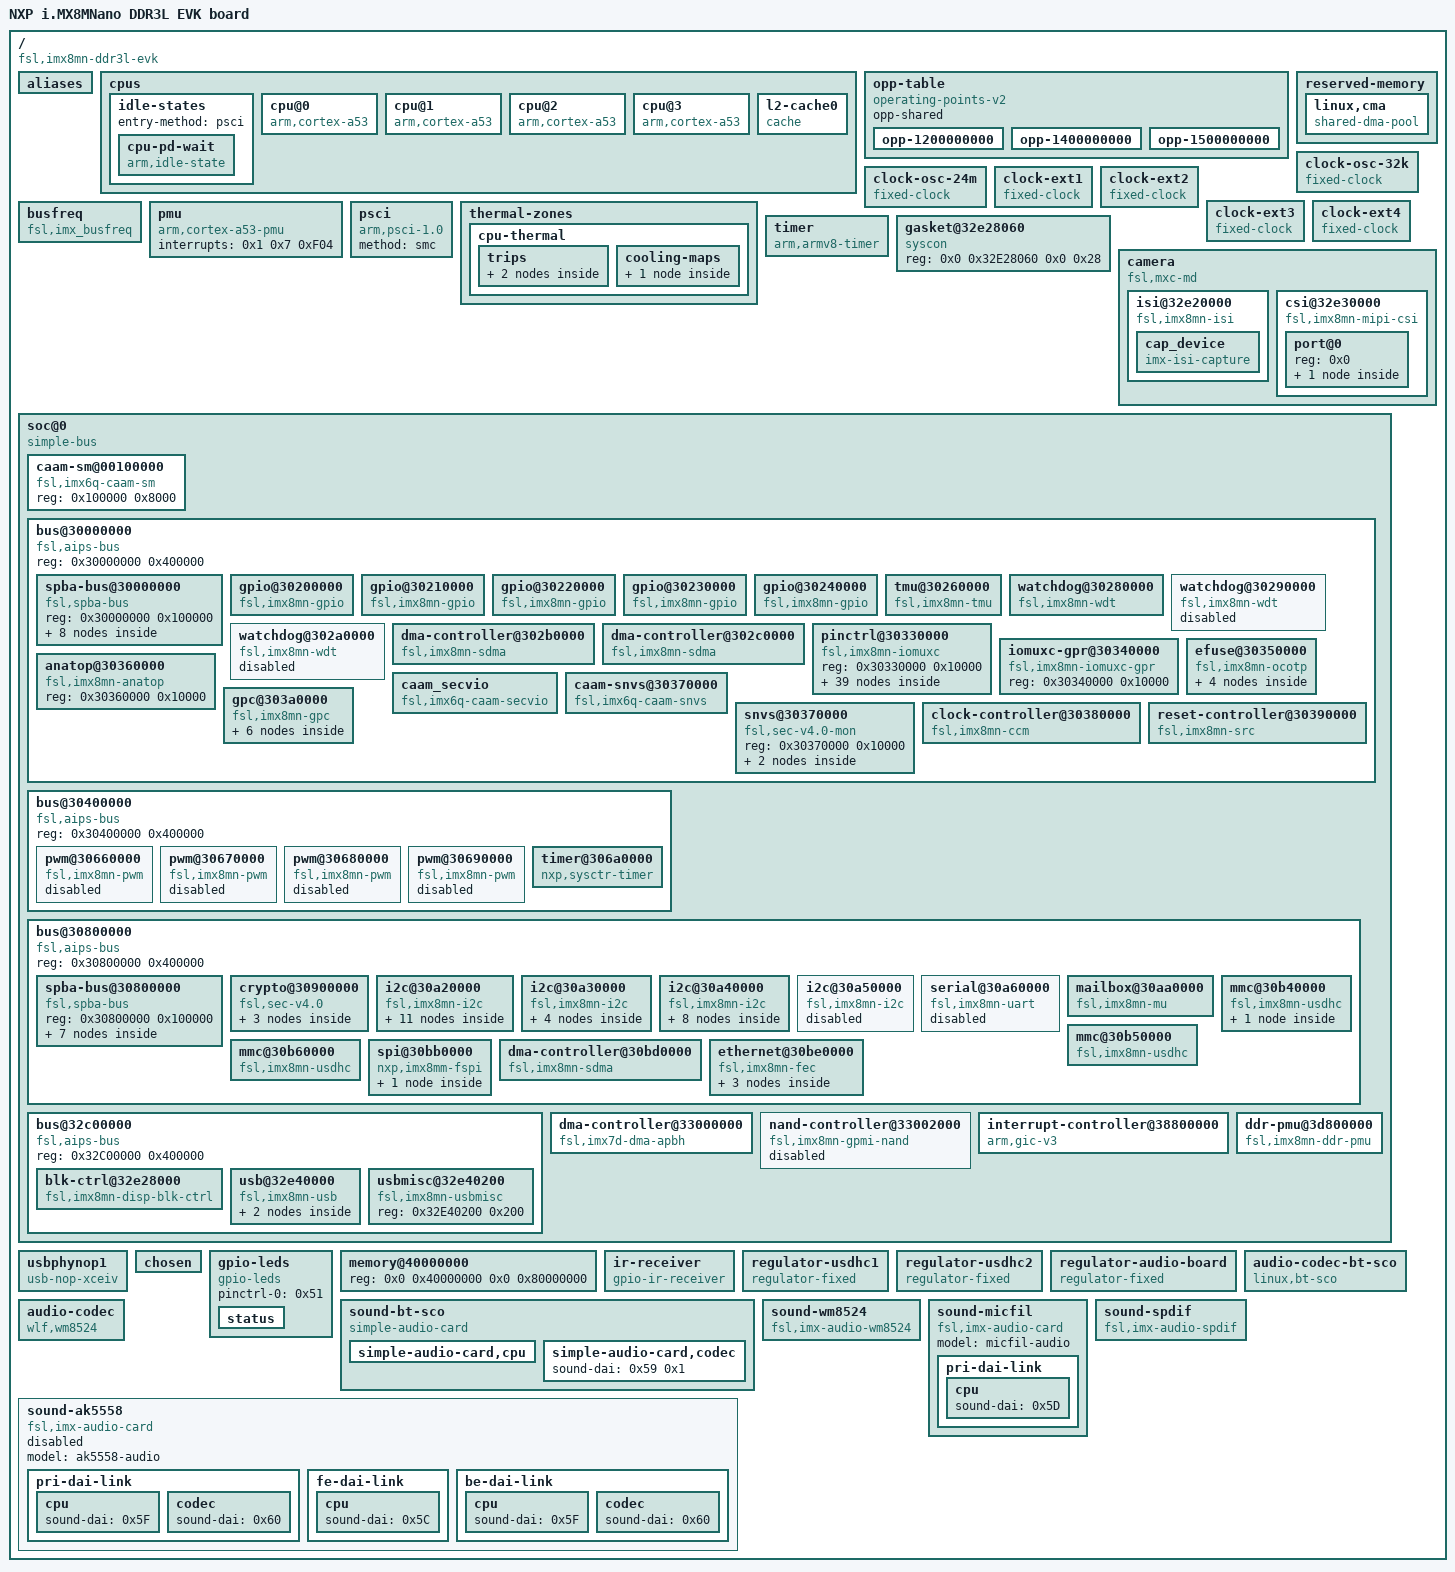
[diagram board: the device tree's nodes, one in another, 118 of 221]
/dts-v1/;
// version: 17
// last_comp_version: 16
// boot_cpuid_phys: 0x0

/ {
    interrupt-parent = <0x1>;
    #address-cells = <0x2>;
    #size-cells = <0x2>;
    model = "NXP i.MX8MNano DDR3L EVK board";
    compatible = "fsl,imx8mn-ddr3l-evk", "fsl,imx8mn";
    aliases {
        ethernet0 = "/soc@0/bus@30800000/ethernet@30be0000";
        gpio0 = "/soc@0/bus@30000000/gpio@30200000";
        gpio1 = "/soc@0/bus@30000000/gpio@30210000";
        gpio2 = "/soc@0/bus@30000000/gpio@30220000";
        gpio3 = "/soc@0/bus@30000000/gpio@30230000";
        gpio4 = "/soc@0/bus@30000000/gpio@30240000";
        i2c0 = "/soc@0/bus@30800000/i2c@30a20000";
        i2c1 = "/soc@0/bus@30800000/i2c@30a30000";
        i2c2 = "/soc@0/bus@30800000/i2c@30a40000";
        i2c3 = "/soc@0/bus@30800000/i2c@30a50000";
        mmc0 = "/soc@0/bus@30800000/mmc@30b40000";
        mmc1 = "/soc@0/bus@30800000/mmc@30b50000";
        mmc2 = "/soc@0/bus@30800000/mmc@30b60000";
        serial0 = "/soc@0/bus@30800000/spba-bus@30800000/serial@30860000";
        serial1 = "/soc@0/bus@30800000/spba-bus@30800000/serial@30890000";
        serial2 = "/soc@0/bus@30800000/spba-bus@30800000/serial@30880000";
        serial3 = "/soc@0/bus@30800000/serial@30a60000";
        spi0 = "/soc@0/bus@30800000/spba-bus@30800000/spi@30820000";
        spi1 = "/soc@0/bus@30800000/spba-bus@30800000/spi@30830000";
        spi2 = "/soc@0/bus@30800000/spba-bus@30800000/spi@30840000";
        isi0 = "/camera/isi@32e20000";
        csi0 = "/camera/csi@32e30000";
    };
    cpus {
        #address-cells = <0x1>;
        #size-cells = <0x0>;
        idle-states {
            entry-method = "psci";
            cpu-pd-wait {
                compatible = "arm,idle-state";
                arm,psci-suspend-param = <0x10033>;
                local-timer-stop;
                entry-latency-us = <0x3E8>;
                exit-latency-us = <0x2BC>;
                min-residency-us = <0xA8C>;
                phandle = <0x6>;
            };
        };
        cpu@0 {
            device_type = "cpu";
            compatible = "arm,cortex-a53";
            reg = <0x0>;
            clock-latency = <0xEE6C>;
            clocks = <0x2 0xBF>;
            enable-method = "psci";
            i-cache-size = <0x8000>;
            i-cache-line-size = <0x40>;
            i-cache-sets = <0x100>;
            d-cache-size = <0x8000>;
            d-cache-line-size = <0x40>;
            d-cache-sets = <0x80>;
            next-level-cache = <0x3>;
            operating-points-v2 = <0x4>;
            nvmem-cells = <0x5>;
            nvmem-cell-names = "speed_grade";
            cpu-idle-states = <0x6>;
            #cooling-cells = <0x2>;
            cpu-supply = <0x7>;
            phandle = <0xA>;
        };
        cpu@1 {
            device_type = "cpu";
            compatible = "arm,cortex-a53";
            reg = <0x1>;
            clock-latency = <0xEE6C>;
            clocks = <0x2 0xBF>;
            enable-method = "psci";
            i-cache-size = <0x8000>;
            i-cache-line-size = <0x40>;
            i-cache-sets = <0x100>;
            d-cache-size = <0x8000>;
            d-cache-line-size = <0x40>;
            d-cache-sets = <0x80>;
            next-level-cache = <0x3>;
            operating-points-v2 = <0x4>;
            cpu-idle-states = <0x6>;
            #cooling-cells = <0x2>;
            cpu-supply = <0x7>;
            phandle = <0xB>;
        };
        cpu@2 {
            device_type = "cpu";
            compatible = "arm,cortex-a53";
            reg = <0x2>;
            clock-latency = <0xEE6C>;
            clocks = <0x2 0xBF>;
            enable-method = "psci";
            i-cache-size = <0x8000>;
            i-cache-line-size = <0x40>;
            i-cache-sets = <0x100>;
            d-cache-size = <0x8000>;
            d-cache-line-size = <0x40>;
            d-cache-sets = <0x80>;
            next-level-cache = <0x3>;
            operating-points-v2 = <0x4>;
            cpu-idle-states = <0x6>;
            #cooling-cells = <0x2>;
            cpu-supply = <0x7>;
            phandle = <0xC>;
        };
        cpu@3 {
            device_type = "cpu";
            compatible = "arm,cortex-a53";
            reg = <0x3>;
            clock-latency = <0xEE6C>;
            clocks = <0x2 0xBF>;
            enable-method = "psci";
            i-cache-size = <0x8000>;
            i-cache-line-size = <0x40>;
            i-cache-sets = <0x100>;
            d-cache-size = <0x8000>;
            d-cache-line-size = <0x40>;
            d-cache-sets = <0x80>;
            next-level-cache = <0x3>;
            operating-points-v2 = <0x4>;
            cpu-idle-states = <0x6>;
            #cooling-cells = <0x2>;
            cpu-supply = <0x7>;
            phandle = <0xD>;
        };
        l2-cache0 {
            compatible = "cache";
            cache-level = <0x2>;
            cache-size = <0x80000>;
            cache-line-size = <0x40>;
            cache-sets = <0x200>;
            phandle = <0x3>;
        };
    };
    opp-table {
        compatible = "operating-points-v2";
        opp-shared;
        phandle = <0x4>;
        opp-1200000000 {
            opp-hz = <0x0 0x47868C00>;
            opp-microvolt = <0xCF850>;
            opp-supported-hw = <0xB00 0x7>;
            clock-latency-ns = <0x249F0>;
            opp-suspend;
        };
        opp-1400000000 {
            opp-hz = <0x0 0x53724E00>;
            opp-microvolt = <0xE7EF0>;
            opp-supported-hw = <0x300 0x7>;
            clock-latency-ns = <0x249F0>;
            opp-suspend;
        };
        opp-1500000000 {
            opp-hz = <0x0 0x59682F00>;
            opp-microvolt = <0xF4240>;
            opp-supported-hw = <0x100 0x3>;
            clock-latency-ns = <0x249F0>;
            opp-suspend;
        };
    };
    reserved-memory {
        #address-cells = <0x2>;
        #size-cells = <0x2>;
        ranges;
        linux,cma {
            compatible = "shared-dma-pool";
            reusable;
            size = <0x0 0x28000000>;
            alloc-ranges = <0x0 0x40000000 0x0 0x40000000>;
            linux,cma-default;
        };
    };
    clock-osc-32k {
        compatible = "fixed-clock";
        #clock-cells = <0x0>;
        clock-frequency = <0x8000>;
        clock-output-names = "osc_32k";
        phandle = <0x1B>;
    };
    clock-osc-24m {
        compatible = "fixed-clock";
        #clock-cells = <0x0>;
        clock-frequency = <0x16E3600>;
        clock-output-names = "osc_24m";
        phandle = <0x1C>;
    };
    clock-ext1 {
        compatible = "fixed-clock";
        #clock-cells = <0x0>;
        clock-frequency = <0x7ED6B40>;
        clock-output-names = "clk_ext1";
        phandle = <0x1D>;
    };
    clock-ext2 {
        compatible = "fixed-clock";
        #clock-cells = <0x0>;
        clock-frequency = <0x7ED6B40>;
        clock-output-names = "clk_ext2";
        phandle = <0x1E>;
    };
    clock-ext3 {
        compatible = "fixed-clock";
        #clock-cells = <0x0>;
        clock-frequency = <0x7ED6B40>;
        clock-output-names = "clk_ext3";
        phandle = <0x1F>;
    };
    clock-ext4 {
        compatible = "fixed-clock";
        #clock-cells = <0x0>;
        clock-frequency = <0x7ED6B40>;
        clock-output-names = "clk_ext4";
        phandle = <0x20>;
    };
    busfreq {
        compatible = "fsl,imx_busfreq";
        clocks = <0x2 0x29 0x2 0x59 0x2 0x5A 0x2 0x5A 0x2 0x58 0x2 0x5B 0x2 0x30 0x2 0x32 0x2 0x3F 0x2 0x53 0x2 0x54 0x2 0x4B 0x2 0x2 0x2 0x38 0x2 0x15>;
        clock-names = "dram_pll", "dram_alt_src", "dram_apb_src", "dram_apb_pre_div", "dram_core", "dram_alt_root", "sys_pll1_40m", "sys_pll1_100m", "sys_pll2_333m", "noc_div", "ahb_div", "main_axi_src", "osc_24m", "sys_pll1_800m", "dram_pll_div";
    };
    pmu {
        compatible = "arm,cortex-a53-pmu";
        interrupts = <0x1 0x7 0xF04>;
    };
    psci {
        compatible = "arm,psci-1.0";
        method = "smc";
    };
    thermal-zones {
        cpu-thermal {
            polling-delay-passive = <0xFA>;
            polling-delay = <0x7D0>;
            thermal-sensors = <0x8>;
            trips {
                trip0 {
                    temperature = <0x14C08>;
                    hysteresis = <0x7D0>;
                    type = "passive";
                    phandle = <0x9>;
                };
                trip1 {
                    temperature = <0x17318>;
                    hysteresis = <0x7D0>;
                    type = "critical";
                };
            };
            cooling-maps {
                map0 {
                    trip = <0x9>;
                    cooling-device = <0xA 0xFFFFFFFF 0xFFFFFFFF 0xB 0xFFFFFFFF 0xFFFFFFFF 0xC 0xFFFFFFFF 0xFFFFFFFF 0xD 0xFFFFFFFF 0xFFFFFFFF>;
                };
            };
        };
    };
    timer {
        compatible = "arm,armv8-timer";
        interrupts = <0x1 0xD 0xF08 0x1 0xE 0xF08 0x1 0xB 0xF08 0x1 0xA 0xF08>;
        clock-frequency = <0x7A1200>;
        arm,no-tick-in-suspend;
    };
    gasket@32e28060 {
        compatible = "syscon";
        reg = <0x0 0x32E28060 0x0 0x28>;
        phandle = <0xF>;
    };
    camera {
        compatible = "fsl,mxc-md", "simple-bus";
        #address-cells = <0x2>;
        #size-cells = <0x2>;
        ranges;
        status = "okay";
        isi@32e20000 {
            compatible = "fsl,imx8mn-isi";
            reg = <0x0 0x32E20000 0x0 0x2000>;
            power-domains = <0xE 0x3>;
            interrupts = <0x0 0x10 0x4>;
            interface = <0x2 0x0 0x2>;
            clocks = <0x2 0x4E 0x2 0x4F 0x2 0xB8 0x2 0xB9>;
            clock-names = "disp_axi", "disp_apb", "disp_axi_root", "disp_apb_root";
            assigned-clocks = <0x2 0xB8 0x2 0xB9>;
            assigned-clock-rates = <0x1DCD6500 0xBEBC200>;
            no-reset-control;
            status = "okay";
            cap_device {
                compatible = "imx-isi-capture";
                status = "okay";
            };
        };
        csi@32e30000 {
            compatible = "fsl,imx8mn-mipi-csi";
            reg = <0x0 0x32E30000 0x0 0x10000>;
            interrupts = <0x0 0x11 0x4>;
            clock-frequency = <0x13D92D40>;
            clocks = <0x2 0x81 0x2 0xB8 0x2 0xB9>;
            clock-names = "mipi_clk", "disp_axi", "disp_apb";
            assigned-clocks = <0x2 0x81>;
            assigned-clock-parents = <0x2 0x41>;
            assigned-clock-rates = <0x13D92D40>;
            bus-width = <0x4>;
            csi-gpr = <0xF>;
            power-domains = <0xE 0x1>;
            status = "okay";
            #address-cells = <0x1>;
            #size-cells = <0x0>;
            port@0 {
                reg = <0x0>;
                endpoint {
                    remote-endpoint = <0x10>;
                    data-lanes = <0x2>;
                    csis-hs-settle = <0xD>;
                    csis-clk-settle = <0x2>;
                    csis-wclk;
                    phandle = <0x35>;
                };
            };
        };
    };
    soc@0 {
        compatible = "simple-bus";
        #address-cells = <0x1>;
        #size-cells = <0x1>;
        ranges = <0x0 0x0 0x0 0x3E000000>;
        dma-ranges = <0x40000000 0x0 0x40000000 0xC0000000>;
        nvmem-cells = <0x11>;
        nvmem-cell-names = "soc_unique_id";
        caam-sm@00100000 {
            compatible = "fsl,imx6q-caam-sm";
            reg = <0x100000 0x8000>;
        };
        bus@30000000 {
            compatible = "fsl,aips-bus", "simple-bus";
            reg = <0x30000000 0x400000>;
            #address-cells = <0x1>;
            #size-cells = <0x1>;
            ranges;
            spba-bus@30000000 {
                compatible = "fsl,spba-bus", "simple-bus";
                #address-cells = <0x1>;
                #size-cells = <0x1>;
                reg = <0x30000000 0x100000>;
                ranges;
                sai@30020000 {
                    compatible = "fsl,imx8mn-sai", "fsl,imx8mq-sai";
                    reg = <0x30020000 0x10000>;
                    #sound-dai-cells = <0x0>;
                    interrupts = <0x0 0x60 0x4>;
                    clocks = <0x2 0x9E 0x2 0x0 0x2 0x9D 0x2 0x0 0x2 0x0>;
                    clock-names = "bus", "mclk0", "mclk1", "mclk2", "mclk3";
                    dmas = <0x12 0x2 0x2 0x0 0x12 0x3 0x2 0x0>;
                    dma-names = "rx", "tx";
                    status = "okay";
                    pinctrl-names = "default";
                    pinctrl-0 = <0x13>;
                    assigned-clocks = <0x2 0x5D>;
                    assigned-clock-parents = <0x2 0x26>;
                    assigned-clock-rates = <0x1770000>;
                    fsl,sai-mclk-direction-output;
                    phandle = <0x58>;
                };
                sai@30030000 {
                    compatible = "fsl,imx8mn-sai", "fsl,imx8mq-sai";
                    reg = <0x30030000 0x10000>;
                    #sound-dai-cells = <0x0>;
                    interrupts = <0x0 0x32 0x4>;
                    clocks = <0x2 0xA0 0x2 0x0 0x2 0x9F 0x2 0x0 0x2 0x0>;
                    clock-names = "bus", "mclk0", "mclk1", "mclk2", "mclk3";
                    dmas = <0x12 0x4 0x2 0x0 0x12 0x5 0x2 0x0>;
                    dma-names = "rx", "tx";
                    status = "okay";
                    pinctrl-names = "default";
                    pinctrl-0 = <0x14>;
                    assigned-clocks = <0x2 0x5E>;
                    assigned-clock-parents = <0x2 0x26>;
                    assigned-clock-rates = <0x1770000>;
                    fsl,sai-mclk-direction-output;
                    phandle = <0x5A>;
                };
                sai@30050000 {
                    compatible = "fsl,imx8mn-sai", "fsl,imx8mq-sai";
                    reg = <0x30050000 0x10000>;
                    #sound-dai-cells = <0x0>;
                    interrupts = <0x0 0x5A 0x4>;
                    clocks = <0x2 0xA2 0x2 0x0 0x2 0xA1 0x2 0x0 0x2 0x0 0x2 0x26 0x2 0x27>;
                    clock-names = "bus", "mclk0", "mclk1", "mclk2", "mclk3", "pll8k", "pll11k";
                    dmas = <0x12 0x8 0x19 0x0 0x12 0x9 0x19 0x0>;
                    dma-names = "rx", "tx";
                    fsl,shared-interrupt;
                    fsl,dataline = <0x0 0xF 0xF>;
                    status = "disabled";
                    pinctrl-names = "default";
                    pinctrl-0 = <0x15>;
                    assigned-clocks = <0x2 0x5F>;
                    assigned-clock-parents = <0x2 0x26>;
                    assigned-clock-rates = <0x2EE0000>;
                    fsl,sai-asynchronous;
                    fsl,sai-multi-lane;
                    fsl,sai-mclk-direction-output;
                    phandle = <0x5F>;
                };
                sai@30060000 {
                    compatible = "fsl,imx8mn-sai", "fsl,imx8mq-sai";
                    reg = <0x30060000 0x10000>;
                    #sound-dai-cells = <0x0>;
                    interrupts = <0x0 0x5A 0x4>;
                    clocks = <0x2 0xA4 0x2 0x0 0x2 0xA3 0x2 0x0 0x2 0x0>;
                    clock-names = "bus", "mclk0", "mclk1", "mclk2", "mclk3";
                    dmas = <0x12 0xA 0x2 0x0 0x12 0xB 0x2 0x0>;
                    dma-names = "rx", "tx";
                    status = "disabled";
                };
                audio-controller@30080000 {
                    compatible = "fsl,imx8mm-micfil";
                    reg = <0x30080000 0x10000>;
                    interrupts = <0x0 0x6D 0x4 0x0 0x6E 0x4 0x0 0x2C 0x4 0x0 0x2D 0x4>;
                    clocks = <0x2 0xB7 0x2 0xB6 0x2 0x26 0x2 0x27 0x2 0x6>;
                    clock-names = "ipg_clk", "ipg_clk_app", "pll8k", "pll11k", "clkext3";
                    dmas = <0x12 0x18 0x19 0x80000000>;
                    dma-names = "rx";
                    status = "okay";
                    #sound-dai-cells = <0x0>;
                    pinctrl-names = "default";
                    pinctrl-0 = <0x16>;
                    assigned-clocks = <0x2 0x86>;
                    assigned-clock-parents = <0x2 0x26>;
                    assigned-clock-rates = <0xBB80000>;
                    phandle = <0x5D>;
                };
                spdif@30090000 {
                    compatible = "fsl,imx35-spdif";
                    reg = <0x30090000 0x10000>;
                    interrupts = <0x0 0x6 0x4>;
                    clocks = <0x2 0x55 0x2 0x2 0x2 0x61 0x2 0x0 0x2 0x0 0x2 0x0 0x2 0x55 0x2 0x0 0x2 0x0 0x2 0x0 0x2 0x26 0x2 0x27>;
                    clock-names = "core", "rxtx0", "rxtx1", "rxtx2", "rxtx3", "rxtx4", "rxtx5", "rxtx6", "rxtx7", "spba", "pll8k", "pll11k";
                    dmas = <0x12 0x1C 0x12 0x0 0x12 0x1D 0x12 0x0>;
                    dma-names = "rx", "tx";
                    status = "okay";
                    pinctrl-names = "default";
                    pinctrl-0 = <0x17>;
                    assigned-clocks = <0x2 0x61>;
                    assigned-clock-parents = <0x2 0x26>;
                    assigned-clock-rates = <0x1770000>;
                    phandle = <0x5E>;
                };
                sai@300b0000 {
                    compatible = "fsl,imx8mn-sai", "fsl,imx8mq-sai";
                    reg = <0x300B0000 0x10000>;
                    #sound-dai-cells = <0x0>;
                    interrupts = <0x0 0x6F 0x4>;
                    clocks = <0x2 0xA6 0x2 0x0 0x2 0xA5 0x2 0x0 0x2 0x0>;
                    clock-names = "bus", "mclk0", "mclk1", "mclk2", "mclk3";
                    dmas = <0x12 0xC 0x2 0x0 0x12 0xD 0x2 0x0>;
                    dma-names = "rx", "tx";
                    status = "disabled";
                };
                easrc@300c0000 {
                    compatible = "fsl,imx8mn-easrc";
                    reg = <0x300C0000 0x10000>;
                    interrupts = <0x0 0x7A 0x4>;
                    clocks = <0x2 0xB4>;
                    clock-names = "mem";
                    dmas = <0x12 0x10 0x17 0x0 0x12 0x11 0x17 0x0 0x12 0x12 0x17 0x0 0x12 0x13 0x17 0x0 0x12 0x14 0x17 0x0 0x12 0x15 0x17 0x0 0x12 0x16 0x17 0x0 0x12 0x17 0x17 0x0>;
                    dma-names = "ctx0_rx", "ctx0_tx", "ctx1_rx", "ctx1_tx", "ctx2_rx", "ctx2_tx", "ctx3_rx", "ctx3_tx";
                    firmware-name = "imx/easrc/easrc-imx8mn.bin";
                    fsl,asrc-rate = <0xBB80>;
                    fsl,asrc-format = <0x2>;
                    status = "okay";
                    #sound-dai-cells = <0x0>;
                    phandle = <0x5C>;
                };
            };
            gpio@30200000 {
                compatible = "fsl,imx8mn-gpio", "fsl,imx35-gpio";
                reg = <0x30200000 0x10000>;
                interrupts = <0x0 0x40 0x4 0x0 0x41 0x4>;
                clocks = <0x2 0x8C>;
                gpio-controller;
                #gpio-cells = <0x2>;
                interrupt-controller;
                #interrupt-cells = <0x2>;
                gpio-ranges = <0x18 0x0 0xA 0x1E>;
                phandle = <0x28>;
            };
            gpio@30210000 {
                compatible = "fsl,imx8mn-gpio", "fsl,imx35-gpio";
                reg = <0x30210000 0x10000>;
                interrupts = <0x0 0x42 0x4 0x0 0x43 0x4>;
                clocks = <0x2 0x8D>;
                gpio-controller;
                #gpio-cells = <0x2>;
                interrupt-controller;
                #interrupt-cells = <0x2>;
                gpio-ranges = <0x18 0x0 0x28 0x15>;
                phandle = <0x2D>;
            };
            gpio@30220000 {
                compatible = "fsl,imx8mn-gpio", "fsl,imx35-gpio";
                reg = <0x30220000 0x10000>;
                interrupts = <0x0 0x44 0x4 0x0 0x45 0x4>;
                clocks = <0x2 0x8E>;
                gpio-controller;
                #gpio-cells = <0x2>;
                interrupt-controller;
                #interrupt-cells = <0x2>;
                gpio-ranges = <0x18 0x0 0x3D 0x1A>;
                phandle = <0x52>;
            };
            gpio@30230000 {
                compatible = "fsl,imx8mn-gpio", "fsl,imx35-gpio";
                reg = <0x30230000 0x10000>;
                interrupts = <0x0 0x46 0x4 0x0 0x47 0x4>;
                clocks = <0x2 0x8F>;
                gpio-controller;
                #gpio-cells = <0x2>;
                interrupt-controller;
                #interrupt-cells = <0x2>;
                gpio-ranges = <0x18 0x15 0x6C 0xB>;
                phandle = <0x48>;
            };
            gpio@30240000 {
                compatible = "fsl,imx8mn-gpio", "fsl,imx35-gpio";
                reg = <0x30240000 0x10000>;
                interrupts = <0x0 0x48 0x4 0x0 0x49 0x4>;
                clocks = <0x2 0x90>;
                gpio-controller;
                #gpio-cells = <0x2>;
                interrupt-controller;
                #interrupt-cells = <0x2>;
                gpio-ranges = <0x18 0x0 0x77 0x1E>;
                phandle = <0x2B>;
            };
            tmu@30260000 {
                compatible = "fsl,imx8mn-tmu", "fsl,imx8mm-tmu";
                reg = <0x30260000 0x10000>;
                clocks = <0x2 0xBE>;
                #thermal-sensor-cells = <0x0>;
                phandle = <0x8>;
            };
            watchdog@30280000 {
                compatible = "fsl,imx8mn-wdt", "fsl,imx21-wdt";
                reg = <0x30280000 0x10000>;
                interrupts = <0x0 0x4E 0x4>;
                clocks = <0x2 0xB0>;
                status = "okay";
                pinctrl-names = "default";
                pinctrl-0 = <0x19>;
                fsl,ext-reset-output;
            };
            watchdog@30290000 {
                compatible = "fsl,imx8mn-wdt", "fsl,imx21-wdt";
                reg = <0x30290000 0x10000>;
                interrupts = <0x0 0x4F 0x4>;
                clocks = <0x2 0xB1>;
                status = "disabled";
            };
            watchdog@302a0000 {
                compatible = "fsl,imx8mn-wdt", "fsl,imx21-wdt";
                reg = <0x302A0000 0x10000>;
                interrupts = <0x0 0xA 0x4>;
                clocks = <0x2 0xB2>;
                status = "disabled";
            };
            dma-controller@302b0000 {
                compatible = "fsl,imx8mn-sdma", "fsl,imx8mq-sdma", "fsl,imx7d-sdma";
                reg = <0x302B0000 0x10000>;
                interrupts = <0x0 0x22 0x4>;
                clocks = <0x2 0xBD 0x2 0xBD>;
                clock-names = "ipg", "ahb";
                #dma-cells = <0x3>;
                fsl,sdma-ram-script-name = "imx/sdma/sdma-imx7d.bin";
            };
            dma-controller@302c0000 {
                compatible = "fsl,imx8mn-sdma", "fsl,imx8mq-sdma", "fsl,imx7d-sdma";
                reg = <0x302C0000 0x10000>;
                interrupts = <0x0 0x67 0x4>;
                clocks = <0x2 0xA8 0x2 0xA8>;
                clock-names = "ipg", "ahb";
                #dma-cells = <0x3>;
                fsl,sdma-ram-script-name = "imx/sdma/sdma-imx7d.bin";
                phandle = <0x12>;
            };
            pinctrl@30330000 {
                compatible = "fsl,imx8mn-iomuxc";
                reg = <0x30330000 0x10000>;
                phandle = <0x18>;
                csi_pwn_grp {
                    fsl,pins = <0x44 0x2AC 0x0 0x0 0x0 0x19>;
                    phandle = <0x33>;
                };
                csi_rst_grp {
                    fsl,pins = <0x40 0x2A8 0x0 0x0 0x0 0x19 0x60 0x2C8 0x0 0x6 0x0 0x59>;
                    phandle = <0x34>;
                };
                ir-recv {
                    fsl,pins = <0x5C 0x2C4 0x0 0x0 0x0 0x4F>;
                };
                fec1grp {
                    fsl,pins = <0x68 0x2D0 0x0 0x0 0x0 0x3 0x6C 0x2D4 0x4C0 0x0 0x1 0x3 0x70 0x2D8 0x0 0x0 0x0 0x1F 0x74 0x2DC 0x0 0x0 0x0 0x1F 0x78 0x2E0 0x0 0x0 0x0 0x1F 0x7C 0x2E4 0x0 0x0 0x0 0x1F 0x9C 0x304 0x0 0x0 0x0 0x91 0x98 0x300 0x0 0x0 0x0 0x91 0x94 0x2FC 0x554 0x0 0x0 0x91 0x90 0x2F8 0x57C 0x0 0x0 0x91 0x84 0x2EC 0x0 0x0 0x0 0x1F 0x8C 0x2F4 0x0 0x0 0x0 0x91 0x88 0x2F0 0x574 0x0 0x0 0x91 0x80 0x2E8 0x0 0x0 0x0 0x1F 0x1B4 0x41C 0x0 0x5 0x0 0x19>;
                    phandle = <0x46>;
                };
                flexspigrp {
                    fsl,pins = <0xF4 0x35C 0x0 0x1 0x0 0x1C2 0xF8 0x360 0x0 0x1 0x0 0x82 0x10C 0x374 0x0 0x1 0x0 0x82 0x110 0x378 0x0 0x1 0x0 0x82 0x114 0x37C 0x0 0x1 0x0 0x82 0x118 0x380 0x0 0x1 0x0 0x82>;
                    phandle = <0x43>;
                };
                gpioledgrp {
                    fsl,pins = <0x134 0x39C 0x0 0x5 0x0 0x19>;
                    phandle = <0x51>;
                };
                i2c2grp-gpio {
                    fsl,pins = <0x21C 0x484 0x0 0x5 0x0 0x1C3 0x220 0x488 0x0 0x5 0x0 0x1C3>;
                    phandle = <0x2A>;
                };
                synaptics_dsx_iogrp {
                    fsl,pins = <0x4C 0x2B4 0x0 0x0 0x0 0x19>;
                };
                gpiowlfgrp {
                    fsl,pins = <0x230 0x498 0x0 0x5 0x0 0xD6>;
                    phandle = <0x56>;
                };
                irgrp {
                    fsl,pins = <0x5C 0x2C4 0x0 0x0 0x0 0x4F>;
                    phandle = <0x53>;
                };
                i2c1grp {
                    fsl,pins = <0x214 0x47C 0x55C 0x0 0x0 0x400001C3 0x218 0x480 0x56C 0x0 0x0 0x400001C3>;
                    phandle = <0x26>;
                };
                i2c2grp {
                    fsl,pins = <0x21C 0x484 0x5D0 0x0 0x0 0x400001C3 0x220 0x488 0x560 0x0 0x0 0x400001C3>;
                    phandle = <0x29>;
                };
                i2c3grp {
                    fsl,pins = <0x224 0x48C 0x588 0x0 0x0 0x400001C3 0x228 0x490 0x5BC 0x0 0x0 0x400001C3>;
                    phandle = <0x2F>;
                };
                i2c3grp-gpio {
                    fsl,pins = <0x224 0x48C 0x0 0x5 0x0 0x1C3 0x228 0x490 0x0 0x5 0x0 0x1C3>;
                    phandle = <0x30>;
                };
                pmicirqgrp {
                    fsl,pins = <0x34 0x29C 0x0 0x0 0x0 0x141>;
                    phandle = <0x27>;
                };
                mipi_dsi_en {
                    fsl,pins = <0x48 0x2B0 0x0 0x0 0x0 0x16>;
                };
                pdmgrp {
                    fsl,pins = <0x158 0x3C0 0x594 0x0 0x0 0xD6 0x144 0x3AC 0x0 0x4 0x0 0xD6 0x140 0x3A8 0x4E4 0x0 0x0 0xD6 0x148 0x3B0 0x534 0x4 0x0 0xD6 0x14C 0x3B4 0x538 0x4 0x0 0xD6 0x150 0x3B8 0x53C 0x4 0x0 0xD6 0x154 0x3BC 0x540 0x4 0x0 0xD6>;
                    phandle = <0x16>;
                };
                sai5grp {
                    fsl,pins = <0x158 0x3C0 0x594 0x0 0x0 0xD6 0x144 0x3AC 0x4D0 0x0 0x0 0xD6 0x140 0x3A8 0x4E4 0x0 0x0 0xD6 0x148 0x3B0 0x4D4 0x0 0x0 0xD6 0x14C 0x3B4 0x4D8 0x0 0x0 0xD6 0x150 0x3B8 0x4DC 0x0 0x0 0xD6 0x154 0x3BC 0x4E0 0x0 0x0 0xD6>;
                    phandle = <0x15>;
                };
                regusdhc2vmmcgrp {
                    fsl,pins = <0xEC 0x354 0x0 0x5 0x0 0x41>;
                    phandle = <0x55>;
                };
                sai2grp {
                    fsl,pins = <0x1C0 0x428 0x0 0x0 0x0 0xD6 0x1BC 0x424 0x0 0x0 0x0 0xD6 0x1C4 0x42C 0x0 0x0 0x0 0xD6 0x1B8 0x420 0x0 0x0 0x0 0xD6>;
                    phandle = <0x13>;
                };
                sai3grp {
                    fsl,pins = <0x1D8 0x440 0x0 0x0 0x0 0xD6 0x1DC 0x444 0x0 0x0 0x0 0xD6 0x1E4 0x44C 0x5C0 0x0 0x0 0xD6 0x1E0 0x448 0x0 0x0 0x0 0xD6>;
                    phandle = <0x14>;
                };
                spdif1grp {
                    fsl,pins = <0x1E8 0x450 0x0 0x0 0x0 0xD6 0x1EC 0x454 0x5CC 0x0 0x0 0xD6>;
                    phandle = <0x17>;
                };
                typec1grp {
                    fsl,pins = <0xCC 0x334 0x0 0x5 0x0 0x159>;
                    phandle = <0x2C>;
                };
                uart1grp {
                    fsl,pins = <0x234 0x49C 0x4F4 0x0 0x0 0x140 0x238 0x4A0 0x0 0x0 0x0 0x140 0x244 0x4AC 0x0 0x1 0x0 0x140 0x248 0x4B0 0x4F0 0x1 0x1 0x140>;
                    phandle = <0x23>;
                };
                uart2grp {
                    fsl,pins = <0x23C 0x4A4 0x4FC 0x0 0x0 0x140 0x240 0x4A8 0x0 0x0 0x0 0x140>;
                    phandle = <0x25>;
                };
                uart3grp {
                    fsl,pins = <0x1F4 0x45C 0x504 0x1 0x0 0x140 0x1F8 0x460 0x0 0x1 0x0 0x140 0x200 0x468 0x500 0x1 0x1 0x140 0x1FC 0x464 0x0 0x1 0x0 0x140>;
                    phandle = <0x24>;
                };
                regusdhc1vmmcgrp {
                    fsl,pins = <0xC8 0x330 0x0 0x5 0x0 0x141>;
                    phandle = <0x54>;
                };
                usdhc1grp {
                    fsl,pins = <0xA0 0x308 0x0 0x0 0x0 0x190 0xA4 0x30C 0x0 0x0 0x0 0x1D0 0xA8 0x310 0x0 0x0 0x0 0x1D0 0xAC 0x314 0x0 0x0 0x0 0x1D0 0xB0 0x318 0x0 0x0 0x0 0x1D0 0xB4 0x31C 0x0 0x0 0x0 0x1D0>;
                    phandle = <0x36>;
                };
                usdhc1grp100mhz {
                    fsl,pins = <0xA0 0x308 0x0 0x0 0x0 0x194 0xA4 0x30C 0x0 0x0 0x0 0x1D4 0xA8 0x310 0x0 0x0 0x0 0x1D4 0xAC 0x314 0x0 0x0 0x0 0x1D4 0xB0 0x318 0x0 0x0 0x0 0x1D4 0xB4 0x31C 0x0 0x0 0x0 0x1D4>;
                    phandle = <0x38>;
                };
                usdhc1grp200mhz {
                    fsl,pins = <0xA0 0x308 0x0 0x0 0x0 0x196 0xA4 0x30C 0x0 0x0 0x0 0x1D6 0xA8 0x310 0x0 0x0 0x0 0x1D6 0xAC 0x314 0x0 0x0 0x0 0x1D6 0xB0 0x318 0x0 0x0 0x0 0x1D6 0xB4 0x31C 0x0 0x0 0x0 0x1D6>;
                    phandle = <0x39>;
                };
                usdhc2gpiogrp {
                    fsl,pins = <0x64 0x2CC 0x0 0x0 0x0 0x1C4>;
                    phandle = <0x3C>;
                };
                usdhc2grp {
                    fsl,pins = <0xD4 0x33C 0x0 0x0 0x0 0x190 0xD8 0x340 0x0 0x0 0x0 0x1D0 0xDC 0x344 0x0 0x0 0x0 0x1D0 0xE0 0x348 0x0 0x0 0x0 0x1D0 0xE4 0x34C 0x0 0x0 0x0 0x1D0 0xE8 0x350 0x0 0x0 0x0 0x1D0 0x38 0x2A0 0x0 0x1 0x0 0x1D0>;
                    phandle = <0x3B>;
                };
                usdhc2-100mhzgrp {
                    fsl,pins = <0xD4 0x33C 0x0 0x0 0x0 0x194 0xD8 0x340 0x0 0x0 0x0 0x1D4 0xDC 0x344 0x0 0x0 0x0 0x1D4 0xE0 0x348 0x0 0x0 0x0 0x1D4 0xE4 0x34C 0x0 0x0 0x0 0x1D4 0xE8 0x350 0x0 0x0 0x0 0x1D4 0x38 0x2A0 0x0 0x1 0x0 0x1D0>;
                    phandle = <0x3D>;
                };
                usdhc2-200mhzgrp {
                    fsl,pins = <0xD4 0x33C 0x0 0x0 0x0 0x196 0xD8 0x340 0x0 0x0 0x0 0x1D6 0xDC 0x344 0x0 0x0 0x0 0x1D6 0xE0 0x348 0x0 0x0 0x0 0x1D6 0xE4 0x34C 0x0 0x0 0x0 0x1D6 0xE8 0x350 0x0 0x0 0x0 0x1D6 0x38 0x2A0 0x0 0x1 0x0 0x1D0>;
                    phandle = <0x3E>;
                };
                usdhc3grp {
                    fsl,pins = <0x138 0x3A0 0x5A0 0x2 0x0 0x40000190 0x13C 0x3A4 0x5DC 0x2 0x0 0x1D0 0x11C 0x384 0x5B4 0x2 0x0 0x1D0 0x120 0x388 0x5B0 0x2 0x0 0x1D0 0x124 0x38C 0x5E4 0x2 0x0 0x1D0 0x128 0x390 0x5E0 0x2 0x0 0x1D0 0x130 0x398 0x558 0x2 0x0 0x1D0 0x100 0x368 0x550 0x2 0x0 0x1D0 0x104 0x36C 0x584 0x2 0x0 0x1D0 0x108 0x370 0x54C 0x2 0x0 0x1D0 0xFC 0x364 0x59C 0x2 0x0 0x190>;
                    phandle = <0x40>;
                };
                usdhc3-100mhzgrp {
                    fsl,pins = <0x138 0x3A0 0x5A0 0x2 0x0 0x40000194 0x13C 0x3A4 0x5DC 0x2 0x0 0x1D4 0x11C 0x384 0x5B4 0x2 0x0 0x1D4 0x120 0x388 0x5B0 0x2 0x0 0x1D4 0x124 0x38C 0x5E4 0x2 0x0 0x1D4 0x128 0x390 0x5E0 0x2 0x0 0x1D4 0x130 0x398 0x558 0x2 0x0 0x1D4 0x100 0x368 0x550 0x2 0x0 0x1D4 0x104 0x36C 0x584 0x2 0x0 0x1D4 0x108 0x370 0x54C 0x2 0x0 0x1D4 0xFC 0x364 0x59C 0x2 0x0 0x194>;
                    phandle = <0x41>;
                };
                usdhc3-200mhzgrp {
                    fsl,pins = <0x138 0x3A0 0x5A0 0x2 0x0 0x40000196 0x13C 0x3A4 0x5DC 0x2 0x0 0x1D6 0x11C 0x384 0x5B4 0x2 0x0 0x1D6 0x120 0x388 0x5B0 0x2 0x0 0x1D6 0x124 0x38C 0x5E4 0x2 0x0 0x1D6 0x128 0x390 0x5E0 0x2 0x0 0x1D6 0x130 0x398 0x558 0x2 0x0 0x1D6 0x100 0x368 0x550 0x2 0x0 0x1D6 0x104 0x36C 0x584 0x2 0x0 0x1D6 0x108 0x370 0x54C 0x2 0x0 0x1D6 0xFC 0x364 0x59C 0x2 0x0 0x196>;
                    phandle = <0x42>;
                };
                wdoggrp {
                    fsl,pins = <0x30 0x298 0x0 0x1 0x0 0x166>;
                    phandle = <0x19>;
                };
                wlangrp {
                    fsl,pins = <0x28 0x290 0x0 0x5 0x0 0x141 0xC4 0x32C 0x0 0x5 0x0 0x159>;
                    phandle = <0x37>;
                };
            };
            iomuxc-gpr@30340000 {
                compatible = "fsl,imx8mn-iomuxc-gpr", "syscon";
                reg = <0x30340000 0x10000>;
                phandle = <0x45>;
            };
            efuse@30350000 {
                compatible = "fsl,imx8mn-ocotp", "fsl,imx8mm-ocotp", "syscon", "simple-mfd";
                reg = <0x30350000 0x10000>;
                clocks = <0x2 0x96>;
                #address-cells = <0x1>;
                #size-cells = <0x1>;
                unique-id@4 {
                    reg = <0x4 0x8>;
                    phandle = <0x11>;
                };
                speed-grade@10 {
                    reg = <0x10 0x4>;
                    phandle = <0x5>;
                };
                mac-address@90 {
                    reg = <0x90 0x6>;
                    phandle = <0x44>;
                };
                imx8mn-soc {
                    compatible = "fsl,imx8mn-soc";
                    nvmem-cells = <0x11>;
                    nvmem-cell-names = "soc_unique_id";
                };
            };
            anatop@30360000 {
                compatible = "fsl,imx8mn-anatop", "fsl,imx8mm-anatop", "syscon";
                reg = <0x30360000 0x10000>;
            };
            caam_secvio {
                compatible = "fsl,imx6q-caam-secvio";
                interrupts = <0x0 0x14 0x4>;
                jtag-tamper = "disabled";
                watchdog-tamper = "enabled";
                internal-boot-tamper = "enabled";
                external-pin-tamper = "disabled";
            };
            caam-snvs@30370000 {
                compatible = "fsl,imx6q-caam-snvs";
                reg = <0x30370000 0x10000>;
                clocks = <0x2 0xD3>;
                clock-names = "ipg";
            };
            snvs@30370000 {
                compatible = "fsl,sec-v4.0-mon", "syscon", "simple-mfd";
                reg = <0x30370000 0x10000>;
                phandle = <0x1A>;
                snvs-rtc-lp {
                    compatible = "fsl,sec-v4.0-mon-rtc-lp";
                    regmap = <0x1A>;
                    offset = <0x34>;
                    interrupts = <0x0 0x13 0x4 0x0 0x14 0x4>;
                    clocks = <0x2 0xD3>;
                    clock-names = "snvs-rtc";
                };
                snvs-powerkey {
                    compatible = "fsl,sec-v4.0-pwrkey";
                    regmap = <0x1A>;
                    interrupts = <0x0 0x4 0x4>;
                    clocks = <0x2 0xD3>;
                    clock-names = "snvs-pwrkey";
                    linux,keycode = <0x74>;
                    wakeup-source;
                    status = "okay";
                };
            };
            clock-controller@30380000 {
                compatible = "fsl,imx8mn-ccm";
                reg = <0x30380000 0x10000>;
                #clock-cells = <0x1>;
                clocks = <0x1B 0x1C 0x1D 0x1E 0x1F 0x20>;
                clock-names = "osc_32k", "osc_24m", "clk_ext1", "clk_ext2", "clk_ext3", "clk_ext4";
                assigned-clocks = <0x2 0x42 0x2 0xD6 0x2 0x53 0x2 0x55 0x2 0x57 0x2 0x1B 0x2 0x14 0x2 0x12 0x2 0x13>;
                assigned-clock-parents = <0x2 0x38 0x2 0x2C 0x2 0x2F 0x2 0x38>;
                assigned-clock-rates = <0x0 0x0 0x0 0x17D78400 0x17D78400 0x23C34600 0x3DF582E0 0x17700000 0x15888000>;
                phandle = <0x2>;
            };
            reset-controller@30390000 {
                compatible = "fsl,imx8mn-src", "fsl,imx8mq-src", "syscon";
                reg = <0x30390000 0x10000>;
                interrupts = <0x0 0x59 0x4>;
                #reset-cells = <0x1>;
            };
            gpc@303a0000 {
                compatible = "fsl,imx8mn-gpc";
                reg = <0x303A0000 0x10000>;
                interrupt-parent = <0x1>;
                interrupts = <0x0 0x57 0x4>;
                pgc {
                    #address-cells = <0x1>;
                    #size-cells = <0x0>;
                    power-domain@0 {
                        #power-domain-cells = <0x0>;
                        reg = <0x0>;
                        clocks = <0x2 0x50>;
                        phandle = <0x4D>;
                    };
                    power-domain@1 {
                        #power-domain-cells = <0x0>;
                        reg = <0x1>;
                        phandle = <0x50>;
                    };
                    power-domain@2 {
                        #power-domain-cells = <0x0>;
                        reg = <0x2>;
                        clocks = <0x2 0xC1 0x2 0xD5 0x2 0xB3 0x2 0x52>;
                    };
                    power-domain@3 {
                        #power-domain-cells = <0x0>;
                        reg = <0x3>;
                        clocks = <0x2 0xB8 0x2 0xB9>;
                        phandle = <0x21>;
                    };
                    power-domain@4 {
                        #power-domain-cells = <0x0>;
                        reg = <0x4>;
                        power-domains = <0x21>;
                        phandle = <0x4A>;
                    };
                };
            };
        };
        bus@30400000 {
            compatible = "fsl,aips-bus", "simple-bus";
            reg = <0x30400000 0x400000>;
            #address-cells = <0x1>;
            #size-cells = <0x1>;
            ranges;
            pwm@30660000 {
                compatible = "fsl,imx8mn-pwm", "fsl,imx27-pwm";
                reg = <0x30660000 0x10000>;
                interrupts = <0x0 0x51 0x4>;
                clocks = <0x2 0x97 0x2 0x97>;
                clock-names = "ipg", "per";
                #pwm-cells = <0x3>;
                status = "disabled";
            };
            pwm@30670000 {
                compatible = "fsl,imx8mn-pwm", "fsl,imx27-pwm";
                reg = <0x30670000 0x10000>;
                interrupts = <0x0 0x52 0x4>;
                clocks = <0x2 0x98 0x2 0x98>;
                clock-names = "ipg", "per";
                #pwm-cells = <0x3>;
                status = "disabled";
            };
            pwm@30680000 {
                compatible = "fsl,imx8mn-pwm", "fsl,imx27-pwm";
                reg = <0x30680000 0x10000>;
                interrupts = <0x0 0x53 0x4>;
                clocks = <0x2 0x99 0x2 0x99>;
                clock-names = "ipg", "per";
                #pwm-cells = <0x3>;
                status = "disabled";
            };
            pwm@30690000 {
                compatible = "fsl,imx8mn-pwm", "fsl,imx27-pwm";
                reg = <0x30690000 0x10000>;
                interrupts = <0x0 0x54 0x4>;
                clocks = <0x2 0x9A 0x2 0x9A>;
                clock-names = "ipg", "per";
                #pwm-cells = <0x3>;
                status = "disabled";
            };
            timer@306a0000 {
                compatible = "nxp,sysctr-timer";
                reg = <0x306A0000 0x20000>;
                interrupts = <0x0 0x2F 0x4>;
                clocks = <0x1C>;
                clock-names = "per";
            };
        };
        bus@30800000 {
            compatible = "fsl,aips-bus", "simple-bus";
            reg = <0x30800000 0x400000>;
            #address-cells = <0x1>;
            #size-cells = <0x1>;
            ranges;
            spba-bus@30800000 {
                compatible = "fsl,spba-bus", "simple-bus";
                #address-cells = <0x1>;
                #size-cells = <0x1>;
                reg = <0x30800000 0x100000>;
                ranges;
                spi@30820000 {
                    compatible = "fsl,imx8mn-ecspi", "fsl,imx51-ecspi";
                    #address-cells = <0x1>;
                    #size-cells = <0x0>;
                    reg = <0x30820000 0x10000>;
                    interrupts = <0x0 0x1F 0x4>;
                    clocks = <0x2 0x88 0x2 0x88>;
                    clock-names = "ipg", "per";
                    dmas = <0x22 0x0 0x7 0x1 0x22 0x1 0x7 0x2>;
                    dma-names = "rx", "tx";
                    status = "disabled";
                };
                spi@30830000 {
                    compatible = "fsl,imx8mn-ecspi", "fsl,imx51-ecspi";
                    #address-cells = <0x1>;
                    #size-cells = <0x0>;
                    reg = <0x30830000 0x10000>;
                    interrupts = <0x0 0x20 0x4>;
                    clocks = <0x2 0x89 0x2 0x89>;
                    clock-names = "ipg", "per";
                    dmas = <0x22 0x2 0x7 0x1 0x22 0x3 0x7 0x2>;
                    dma-names = "rx", "tx";
                    status = "disabled";
                };
                spi@30840000 {
                    compatible = "fsl,imx8mn-ecspi", "fsl,imx51-ecspi";
                    #address-cells = <0x1>;
                    #size-cells = <0x0>;
                    reg = <0x30840000 0x10000>;
                    interrupts = <0x0 0x21 0x4>;
                    clocks = <0x2 0x8A 0x2 0x8A>;
                    clock-names = "ipg", "per";
                    dmas = <0x22 0x4 0x7 0x1 0x22 0x5 0x7 0x2>;
                    dma-names = "rx", "tx";
                    status = "disabled";
                };
                serial@30860000 {
                    compatible = "fsl,imx8mn-uart", "fsl,imx6q-uart";
                    reg = <0x30860000 0x10000>;
                    interrupts = <0x0 0x1A 0x4>;
                    clocks = <0x2 0xA9 0x2 0xA9>;
                    clock-names = "ipg", "per";
                    dmas = <0x22 0x16 0x4 0x0 0x22 0x17 0x4 0x0>;
                    dma-names = "rx", "tx";
                    status = "okay";
                    pinctrl-names = "default";
                    pinctrl-0 = <0x23>;
                    assigned-clocks = <0x2 0x6D>;
                    assigned-clock-parents = <0x2 0x31>;
                    fsl,uart-has-rtscts;
                    bluetooth {
                        compatible = "nxp,88w8987-bt";
                    };
                };
                serial@30880000 {
                    compatible = "fsl,imx8mn-uart", "fsl,imx6q-uart";
                    reg = <0x30880000 0x10000>;
                    interrupts = <0x0 0x1C 0x4>;
                    clocks = <0x2 0xAB 0x2 0xAB>;
                    clock-names = "ipg", "per";
                    dmas = <0x22 0x1A 0x4 0x0 0x22 0x1B 0x4 0x0>;
                    dma-names = "rx", "tx";
                    status = "okay";
                    pinctrl-names = "default";
                    pinctrl-0 = <0x24>;
                    assigned-clocks = <0x2 0x6F>;
                    assigned-clock-parents = <0x2 0x31>;
                    uart-has-rtscts;
                };
                serial@30890000 {
                    compatible = "fsl,imx8mn-uart", "fsl,imx6q-uart";
                    reg = <0x30890000 0x10000>;
                    interrupts = <0x0 0x1B 0x4>;
                    clocks = <0x2 0xAA 0x2 0xAA>;
                    clock-names = "ipg", "per";
                    status = "okay";
                    pinctrl-names = "default";
                    pinctrl-0 = <0x25>;
                };
            };
            crypto@30900000 {
                compatible = "fsl,sec-v4.0";
                #address-cells = <0x1>;
                #size-cells = <0x1>;
                reg = <0x30900000 0x40000>;
                ranges = <0x0 0x30900000 0x40000>;
                interrupts = <0x0 0x5B 0x4>;
                clocks = <0x2 0x54 0x2 0x56>;
                clock-names = "aclk", "ipg";
                jr@1000 {
                    compatible = "fsl,sec-v4.0-job-ring";
                    reg = <0x1000 0x1000>;
                    interrupts = <0x0 0x69 0x4>;
                    status = "disabled";
                };
                jr@2000 {
                    compatible = "fsl,sec-v4.0-job-ring";
                    reg = <0x2000 0x1000>;
                    interrupts = <0x0 0x6A 0x4>;
                };
                jr@3000 {
                    compatible = "fsl,sec-v4.0-job-ring";
                    reg = <0x3000 0x1000>;
                    interrupts = <0x0 0x72 0x4>;
                };
            };
            i2c@30a20000 {
                compatible = "fsl,imx8mn-i2c", "fsl,imx21-i2c";
                #address-cells = <0x1>;
                #size-cells = <0x0>;
                reg = <0x30A20000 0x10000>;
                interrupts = <0x0 0x23 0x4>;
                clocks = <0x2 0x91>;
                status = "okay";
                clock-frequency = <0x61A80>;
                pinctrl-names = "default";
                pinctrl-0 = <0x26>;
                pmic@25 {
                    compatible = "nxp,pca9450b";
                    reg = <0x25>;
                    pinctrl-names = "default";
                    pinctrl-0 = <0x27>;
                    interrupt-parent = <0x28>;
                    interrupts = <0x3 0x8>;
                    regulators {
                        BUCK1 {
                            regulator-name = "VDD_SOC_0V9";
                            regulator-min-microvolt = <0xCF850>;
                            regulator-max-microvolt = <0xE7EF0>;
                            regulator-boot-on;
                            regulator-always-on;
                            regulator-ramp-delay = <0xC35>;
                            phandle = <0x7>;
                        };
                        BUCK4 {
                            regulator-name = "VDD_3V3";
                            regulator-min-microvolt = <0x325AA0>;
                            regulator-max-microvolt = <0x325AA0>;
                            regulator-boot-on;
                            regulator-always-on;
                        };
                        BUCK5 {
                            regulator-name = "VDD_1V8";
                            regulator-min-microvolt = <0x1B7740>;
                            regulator-max-microvolt = <0x1B7740>;
                            regulator-boot-on;
                            regulator-always-on;
                        };
                        BUCK6 {
                            regulator-name = "NVCC_DRAM_1V35";
                            regulator-min-microvolt = <0x149970>;
                            regulator-max-microvolt = <0x149970>;
                            regulator-boot-on;
                            regulator-always-on;
                        };
                        LDO1 {
                            regulator-name = "NVCC_SNVS_1V8";
                            regulator-min-microvolt = <0x1B7740>;
                            regulator-max-microvolt = <0x1B7740>;
                            regulator-boot-on;
                            regulator-always-on;
                        };
                        LDO2 {
                            regulator-name = "VDD_SNVS_0V8";
                            regulator-min-microvolt = <0xC3500>;
                            regulator-max-microvolt = <0xC3500>;
                            regulator-boot-on;
                            regulator-always-on;
                        };
                        LDO3 {
                            regulator-name = "VDDA_1V8";
                            regulator-min-microvolt = <0x1B7740>;
                            regulator-max-microvolt = <0x1B7740>;
                            regulator-boot-on;
                            regulator-always-on;
                        };
                        LDO4 {
                            regulator-name = "VDD_PHY_1V2";
                            regulator-min-microvolt = <0x124F80>;
                            regulator-max-microvolt = <0x124F80>;
                            regulator-boot-on;
                            regulator-always-on;
                        };
                        LDO5 {
                            regulator-name = "NVCC_SD2";
                            regulator-min-microvolt = <0x1B7740>;
                            regulator-max-microvolt = <0x325AA0>;
                            regulator-boot-on;
                            regulator-always-on;
                        };
                    };
                };
            };
            i2c@30a30000 {
                compatible = "fsl,imx8mn-i2c", "fsl,imx21-i2c";
                #address-cells = <0x1>;
                #size-cells = <0x0>;
                reg = <0x30A30000 0x10000>;
                interrupts = <0x0 0x24 0x4>;
                clocks = <0x2 0x92>;
                status = "okay";
                clock-frequency = <0x61A80>;
                pinctrl-names = "default", "gpio";
                pinctrl-0 = <0x29>;
                pinctrl-1 = <0x2A>;
                scl-gpios = <0x2B 0x10 0x0>;
                sda-gpios = <0x2B 0x11 0x0>;
                tcpc@50 {
                    compatible = "nxp,ptn5110";
                    pinctrl-names = "default";
                    pinctrl-0 = <0x2C>;
                    reg = <0x50>;
                    interrupt-parent = <0x2D>;
                    interrupts = <0xB 0x8>;
                    status = "okay";
                    port {
                        endpoint {
                            remote-endpoint = <0x2E>;
                            phandle = <0x4E>;
                        };
                    };
                    connector {
                        compatible = "usb-c-connector";
                        label = "USB-C";
                        power-role = "dual";
                        data-role = "dual";
                        try-power-role = "sink";
                        source-pdos = <0x401912C>;
                        sink-pdos = <0x401912C 0x9901912C>;
                        op-sink-microwatt = <0xE4E1C0>;
                        self-powered;
                    };
                };
            };
            i2c@30a40000 {
                #address-cells = <0x1>;
                #size-cells = <0x0>;
                compatible = "fsl,imx8mn-i2c", "fsl,imx21-i2c";
                reg = <0x30A40000 0x10000>;
                interrupts = <0x0 0x25 0x4>;
                clocks = <0x2 0x93>;
                status = "okay";
                clock-frequency = <0x186A0>;
                pinctrl-names = "default", "gpio";
                pinctrl-0 = <0x2F>;
                pinctrl-1 = <0x30>;
                scl-gpios = <0x2B 0x12 0x0>;
                sda-gpios = <0x2B 0x13 0x0>;
                gpio@20 {
                    compatible = "ti,tca6416";
                    reg = <0x20>;
                    gpio-controller;
                    #gpio-cells = <0x2>;
                    phandle = <0x32>;
                };
                ak4458@10 {
                    #sound-dai-cells = <0x0>;
                    compatible = "asahi-kasei,ak4458";
                    reg = <0x10>;
                    AVDD-supply = <0x31>;
                    DVDD-supply = <0x31>;
                    status = "disabled";
                };
                ak4458@12 {
                    #sound-dai-cells = <0x0>;
                    compatible = "asahi-kasei,ak4458";
                    reg = <0x12>;
                    AVDD-supply = <0x31>;
                    DVDD-supply = <0x31>;
                    status = "disabled";
                };
                ak5558@13 {
                    #sound-dai-cells = <0x0>;
                    compatible = "asahi-kasei,ak5558";
                    reg = <0x13>;
                    reset-gpios = <0x32 0x3 0x1>;
                    AVDD-supply = <0x31>;
                    DVDD-supply = <0x31>;
                    status = "disabled";
                    phandle = <0x60>;
                };
                ak4497@11 {
                    #sound-dai-cells = <0x0>;
                    compatible = "asahi-kasei,ak4497";
                    reg = <0x11>;
                    reset-gpios = <0x32 0x5 0x1>;
                    AVDD-supply = <0x31>;
                    DVDD-supply = <0x31>;
                    status = "disabled";
                };
                ov5640_mipi@3c {
                    compatible = "ovti,ov5640";
                    reg = <0x3C>;
                    pinctrl-names = "default";
                    pinctrl-0 = <0x33 0x34>;
                    clocks = <0x2 0x7B>;
                    clock-names = "xclk";
                    assigned-clocks = <0x2 0x7B>;
                    assigned-clock-parents = <0x2 0x2>;
                    assigned-clock-rates = <0x16E3600>;
                    csi_id = <0x0>;
                    powerdown-gpios = <0x28 0x7 0x0>;
                    reset-gpios = <0x28 0x6 0x1>;
                    mclk = <0x16E3600>;
                    mclk_source = <0x0>;
                    mipi_csi;
                    status = "okay";
                    port {
                        endpoint {
                            remote-endpoint = <0x35>;
                            data-lanes = <0x1 0x2>;
                            clocks-lanes = <0x0>;
                            phandle = <0x10>;
                        };
                    };
                };
            };
            i2c@30a50000 {
                compatible = "fsl,imx8mn-i2c", "fsl,imx21-i2c";
                #address-cells = <0x1>;
                #size-cells = <0x0>;
                reg = <0x30A50000 0x10000>;
                interrupts = <0x0 0x26 0x4>;
                clocks = <0x2 0x94>;
                status = "disabled";
            };
            serial@30a60000 {
                compatible = "fsl,imx8mn-uart", "fsl,imx6q-uart";
                reg = <0x30A60000 0x10000>;
                interrupts = <0x0 0x1D 0x4>;
                clocks = <0x2 0xAC 0x2 0xAC>;
                clock-names = "ipg", "per";
                dmas = <0x22 0x1C 0x4 0x0 0x22 0x1D 0x4 0x0>;
                dma-names = "rx", "tx";
                status = "disabled";
            };
            mailbox@30aa0000 {
                compatible = "fsl,imx8mn-mu", "fsl,imx6sx-mu";
                reg = <0x30AA0000 0x10000>;
                interrupts = <0x0 0x58 0x4>;
                clocks = <0x2 0x95>;
                #mbox-cells = <0x2>;
            };
            mmc@30b40000 {
                compatible = "fsl,imx8mn-usdhc", "fsl,imx8mm-usdhc", "fsl,imx7d-usdhc";
                reg = <0x30B40000 0x10000>;
                interrupts = <0x0 0x16 0x4>;
                clocks = <0x2 0x56 0x2 0x4D 0x2 0xAE>;
                clock-names = "ipg", "ahb", "per";
                fsl,tuning-start-tap = <0x14>;
                fsl,tuning-step = <0x2>;
                bus-width = <0x4>;
                status = "okay";
                #address-cells = <0x1>;
                #size-cells = <0x0>;
                pinctrl-names = "default", "state_100mhz", "state_200mhz";
                pinctrl-0 = <0x36 0x37>;
                pinctrl-1 = <0x38 0x37>;
                pinctrl-2 = <0x39 0x37>;
                keep-power-in-suspend;
                non-removable;
                wakeup-source;
                fsl,sdio-async-interrupt-enabled;
                vmmc-supply = <0x3A>;
                wifi_wake_host {
                    compatible = "nxp,wifi-wake-host";
                    interrupt-parent = <0x2D>;
                    interrupts = <0x9 0x8>;
                    interrupt-names = "host-wake";
                };
            };
            mmc@30b50000 {
                compatible = "fsl,imx8mn-usdhc", "fsl,imx8mm-usdhc", "fsl,imx7d-usdhc";
                reg = <0x30B50000 0x10000>;
                interrupts = <0x0 0x17 0x4>;
                clocks = <0x2 0x56 0x2 0x4D 0x2 0xAF>;
                clock-names = "ipg", "ahb", "per";
                fsl,tuning-start-tap = <0x14>;
                fsl,tuning-step = <0x2>;
                bus-width = <0x4>;
                status = "okay";
                assigned-clocks = <0x2 0x68>;
                assigned-clock-rates = <0xBEBC200>;
                pinctrl-names = "default", "state_100mhz", "state_200mhz";
                pinctrl-0 = <0x3B 0x3C>;
                pinctrl-1 = <0x3D 0x3C>;
                pinctrl-2 = <0x3E 0x3C>;
                cd-gpios = <0x28 0xF 0x1>;
                vmmc-supply = <0x3F>;
            };
            mmc@30b60000 {
                compatible = "fsl,imx8mn-usdhc", "fsl,imx8mm-usdhc", "fsl,imx7d-usdhc";
                reg = <0x30B60000 0x10000>;
                interrupts = <0x0 0x18 0x4>;
                clocks = <0x2 0x56 0x2 0x4D 0x2 0xBC>;
                clock-names = "ipg", "ahb", "per";
                fsl,tuning-start-tap = <0x14>;
                fsl,tuning-step = <0x2>;
                bus-width = <0x8>;
                status = "okay";
                assigned-clocks = <0x2 0xBC>;
                assigned-clock-rates = <0x17D78400>;
                pinctrl-names = "default", "state_100mhz", "state_200mhz";
                pinctrl-0 = <0x40>;
                pinctrl-1 = <0x41>;
                pinctrl-2 = <0x42>;
                non-removable;
            };
            spi@30bb0000 {
                #address-cells = <0x1>;
                #size-cells = <0x0>;
                compatible = "nxp,imx8mm-fspi";
                reg = <0x30BB0000 0x10000 0x8000000 0x10000000>;
                reg-names = "fspi_base", "fspi_mmap";
                interrupts = <0x0 0x6B 0x4>;
                clocks = <0x2 0x9B 0x2 0x9B>;
                clock-names = "fspi_en", "fspi";
                status = "okay";
                pinctrl-names = "default";
                pinctrl-0 = <0x43>;
                flash@0 {
                    compatible = "jedec,spi-nor";
                    reg = <0x0>;
                    #address-cells = <0x1>;
                    #size-cells = <0x1>;
                    spi-max-frequency = <0x9E4F580>;
                    spi-tx-bus-width = <0x1>;
                    spi-rx-bus-width = <0x4>;
                };
            };
            dma-controller@30bd0000 {
                compatible = "fsl,imx8mn-sdma", "fsl,imx8mq-sdma", "fsl,imx7d-sdma";
                reg = <0x30BD0000 0x10000>;
                interrupts = <0x0 0x2 0x4>;
                clocks = <0x2 0xA7 0x2 0x54>;
                clock-names = "ipg", "ahb";
                #dma-cells = <0x3>;
                fsl,sdma-ram-script-name = "imx/sdma/sdma-imx7d.bin";
                phandle = <0x22>;
            };
            ethernet@30be0000 {
                compatible = "fsl,imx8mn-fec", "fsl,imx8mq-fec", "fsl,imx6sx-fec";
                reg = <0x30BE0000 0x10000>;
                interrupts = <0x0 0x76 0x4 0x0 0x77 0x4 0x0 0x78 0x4 0x0 0x79 0x4>;
                clocks = <0x2 0x8B 0x2 0x8B 0x2 0x63 0x2 0x62 0x2 0x64>;
                clock-names = "ipg", "ahb", "ptp", "enet_clk_ref", "enet_out";
                assigned-clocks = <0x2 0x4C 0x2 0x63 0x2 0x62 0x2 0x64>;
                assigned-clock-parents = <0x2 0x36 0x2 0x3A 0x2 0x3B 0x2 0x39>;
                assigned-clock-rates = <0x0 0x5F5E100 0x7735940 0x0>;
                fsl,num-tx-queues = <0x3>;
                fsl,num-rx-queues = <0x3>;
                nvmem-cells = <0x44>;
                nvmem-cell-names = "mac-address";
                fsl,stop-mode = <0x45 0x10 0x3>;
                status = "okay";
                pinctrl-names = "default";
                pinctrl-0 = <0x46>;
                phy-mode = "rgmii-id";
                phy-handle = <0x47>;
                fsl,magic-packet;
                mdio {
                    #address-cells = <0x1>;
                    #size-cells = <0x0>;
                    ethernet-phy@0 {
                        compatible = "ethernet-phy-ieee802.3-c22";
                        reg = <0x0>;
                        reset-gpios = <0x48 0x16 0x1>;
                        reset-assert-us = <0x2710>;
                        reset-deassert-us = <0x13880>;
                        realtek,aldps-enable;
                        realtek,clkout-disable;
                        qca,disable-smarteee;
                        vddio-supply = <0x49>;
                        phandle = <0x47>;
                        vddio-regulator {
                            regulator-min-microvolt = <0x1B7740>;
                            regulator-max-microvolt = <0x1B7740>;
                            phandle = <0x49>;
                        };
                    };
                };
            };
        };
        bus@32c00000 {
            compatible = "fsl,aips-bus", "simple-bus";
            reg = <0x32C00000 0x400000>;
            #address-cells = <0x1>;
            #size-cells = <0x1>;
            ranges;
            blk-ctrl@32e28000 {
                compatible = "fsl,imx8mn-disp-blk-ctrl", "syscon";
                reg = <0x32E28000 0x100>;
                power-domains = <0x21 0x21 0x21 0x4A 0x4A>;
                power-domain-names = "bus", "isi", "lcdif", "mipi-dsi", "mipi-csi";
                clocks = <0x2 0x4E 0x2 0x4F 0x2 0xB8 0x2 0xB9 0x2 0xB8 0x2 0xB9 0x2 0xBA 0x2 0x7D 0x2 0x7E 0x2 0x82 0x2 0xBB>;
                clock-names = "disp_axi", "disp_apb", "disp_axi_root", "disp_apb_root", "lcdif-axi", "lcdif-apb", "lcdif-pix", "dsi-pclk", "dsi-ref", "csi-aclk", "csi-pclk";
                #power-domain-cells = <0x1>;
                phandle = <0xE>;
            };
            usb@32e40000 {
                compatible = "fsl,imx8mn-usb", "fsl,imx7d-usb";
                reg = <0x32E40000 0x200>;
                interrupts = <0x0 0x28 0x4>;
                clocks = <0x2 0xAD>;
                clock-names = "usb1_ctrl_root_clk";
                assigned-clocks = <0x2 0x50>;
                assigned-clock-parents = <0x2 0x40>;
                phys = <0x4B>;
                fsl,usbmisc = <0x4C 0x0>;
                power-domains = <0x4D>;
                status = "okay";
                dr_mode = "otg";
                hnp-disable;
                srp-disable;
                adp-disable;
                usb-role-switch;
                disable-over-current;
                samsung,picophy-pre-emp-curr-control = <0x3>;
                samsung,picophy-dc-vol-level-adjust = <0x7>;
                port {
                    endpoint {
                        remote-endpoint = <0x4E>;
                        phandle = <0x2E>;
                    };
                };
            };
            usbmisc@32e40200 {
                compatible = "fsl,imx8mn-usbmisc", "fsl,imx7d-usbmisc";
                #index-cells = <0x1>;
                reg = <0x32E40200 0x200>;
                phandle = <0x4C>;
            };
        };
        dma-controller@33000000 {
            compatible = "fsl,imx7d-dma-apbh", "fsl,imx28-dma-apbh";
            reg = <0x33000000 0x2000>;
            interrupts = <0x0 0xC 0x4 0x0 0xC 0x4 0x0 0xC 0x4 0x0 0xC 0x4>;
            interrupt-names = "gpmi0", "gpmi1", "gpmi2", "gpmi3";
            #dma-cells = <0x1>;
            dma-channels = <0x4>;
            clocks = <0x2 0xC0>;
            phandle = <0x4F>;
        };
        nand-controller@33002000 {
            compatible = "fsl,imx8mn-gpmi-nand", "fsl,imx7d-gpmi-nand";
            #address-cells = <0x1>;
            #size-cells = <0x0>;
            reg = <0x33002000 0x2000 0x33004000 0x4000>;
            reg-names = "gpmi-nand", "bch";
            interrupts = <0x0 0xE 0x4>;
            interrupt-names = "bch";
            clocks = <0x2 0x9C 0x2 0xC0>;
            clock-names = "gpmi_io", "gpmi_bch_apb";
            dmas = <0x4F 0x0>;
            dma-names = "rx-tx";
            status = "disabled";
        };
        interrupt-controller@38800000 {
            compatible = "arm,gic-v3";
            reg = <0x38800000 0x10000 0x38880000 0xC0000>;
            #interrupt-cells = <0x3>;
            interrupt-controller;
            interrupts = <0x1 0x9 0x4>;
            phandle = <0x1>;
        };
        ddr-pmu@3d800000 {
            compatible = "fsl,imx8mn-ddr-pmu", "fsl,imx8m-ddr-pmu";
            reg = <0x3D800000 0x400000>;
            interrupts = <0x0 0x62 0x4>;
        };
    };
    usbphynop1 {
        #phy-cells = <0x0>;
        compatible = "usb-nop-xceiv";
        clocks = <0x2 0x72>;
        assigned-clocks = <0x2 0x72>;
        assigned-clock-parents = <0x2 0x32>;
        clock-names = "main_clk";
        power-domains = <0x50>;
        wakeup-source;
        phandle = <0x4B>;
    };
    chosen {
        stdout-path = "/soc@0/bus@30800000/spba-bus@30800000/serial@30890000";
    };
    gpio-leds {
        compatible = "gpio-leds";
        pinctrl-names = "default";
        pinctrl-0 = <0x51>;
        status {
            label = "yellow:status";
            gpios = <0x52 0x10 0x0>;
            default-state = "on";
        };
    };
    memory@40000000 {
        device_type = "memory";
        reg = <0x0 0x40000000 0x0 0x80000000>;
    };
    ir-receiver {
        compatible = "gpio-ir-receiver";
        gpios = <0x28 0xD 0x1>;
        pinctrl-names = "default";
        pinctrl-0 = <0x53>;
        linux,autosuspend-period = <0x7D>;
    };
    regulator-usdhc1 {
        compatible = "regulator-fixed";
        regulator-name = "WLAN_EN";
        pinctrl-names = "default";
        pinctrl-0 = <0x54>;
        regulator-min-microvolt = <0x325AA0>;
        regulator-max-microvolt = <0x325AA0>;
        gpio = <0x2D 0xA 0x0>;
        enable-active-high;
        phandle = <0x3A>;
    };
    regulator-usdhc2 {
        compatible = "regulator-fixed";
        pinctrl-names = "default";
        pinctrl-0 = <0x55>;
        regulator-name = "VSD_3V3";
        regulator-min-microvolt = <0x325AA0>;
        regulator-max-microvolt = <0x325AA0>;
        gpio = <0x2D 0x13 0x0>;
        off-on-delay-us = <0x2EE0>;
        enable-active-high;
        phandle = <0x3F>;
    };
    regulator-audio-board {
        compatible = "regulator-fixed";
        regulator-name = "EXT_PWREN";
        regulator-min-microvolt = <0x325AA0>;
        regulator-max-microvolt = <0x325AA0>;
        enable-active-high;
        startup-delay-us = <0x493E0>;
        gpio = <0x32 0x1 0x0>;
        regulator-always-on;
        phandle = <0x31>;
    };
    audio-codec-bt-sco {
        compatible = "linux,bt-sco";
        #sound-dai-cells = <0x1>;
        phandle = <0x59>;
    };
    audio-codec {
        #sound-dai-cells = <0x0>;
        compatible = "wlf,wm8524";
        pinctrl-names = "default";
        pinctrl-0 = <0x56>;
        wlf,mute-gpios = <0x2B 0x15 0x1>;
        clocks = <0x2 0x9F>;
        clock-names = "mclk";
        phandle = <0x5B>;
    };
    sound-bt-sco {
        compatible = "simple-audio-card";
        simple-audio-card,name = "bt-sco-audio";
        simple-audio-card,format = "dsp_a";
        simple-audio-card,bitclock-inversion;
        simple-audio-card,frame-master = <0x57>;
        simple-audio-card,bitclock-master = <0x57>;
        simple-audio-card,cpu {
            sound-dai = <0x58>;
            dai-tdm-slot-num = <0x2>;
            dai-tdm-slot-width = <0x10>;
            phandle = <0x57>;
        };
        simple-audio-card,codec {
            sound-dai = <0x59 0x1>;
        };
    };
    sound-wm8524 {
        compatible = "fsl,imx-audio-wm8524";
        model = "wm8524-audio";
        audio-cpu = <0x5A>;
        audio-codec = <0x5B>;
        audio-asrc = <0x5C>;
        audio-routing = "Line Out Jack", "LINEVOUTL", "Line Out Jack", "LINEVOUTR";
    };
    sound-micfil {
        compatible = "fsl,imx-audio-card";
        model = "micfil-audio";
        pri-dai-link {
            link-name = "micfil hifi";
            format = "i2s";
            cpu {
                sound-dai = <0x5D>;
            };
        };
    };
    sound-spdif {
        compatible = "fsl,imx-audio-spdif";
        model = "imx-spdif";
        spdif-controller = <0x5E>;
        spdif-out;
        spdif-in;
    };
    sound-ak5558 {
        compatible = "fsl,imx-audio-card";
        model = "ak5558-audio";
        status = "disabled";
        pri-dai-link {
            link-name = "akcodec";
            format = "i2s";
            fsl,mclk-equal-bclk;
            cpu {
                sound-dai = <0x5F>;
            };
            codec {
                sound-dai = <0x60>;
            };
        };
        fe-dai-link {
            link-name = "HiFi-ASRC-FE";
            format = "i2s";
            cpu {
                sound-dai = <0x5C>;
            };
        };
        be-dai-link {
            link-name = "HiFi-ASRC-BE";
            format = "dsp_b";
            dai-tdm-slot-num = <0x8>;
            dai-tdm-slot-width = <0x20>;
            cpu {
                sound-dai = <0x5F>;
            };
            codec {
                sound-dai = <0x60>;
            };
        };
    };
};
